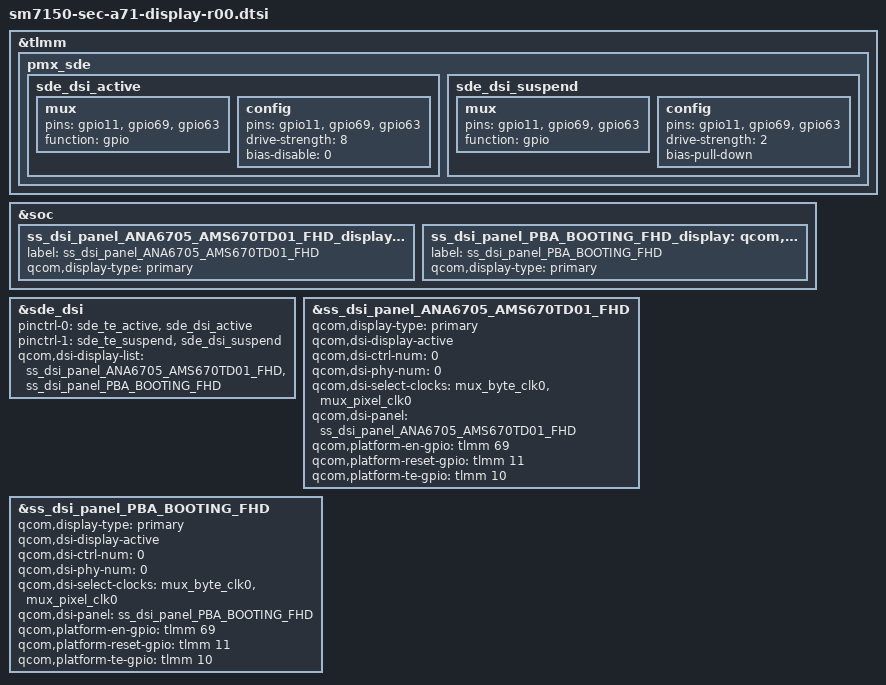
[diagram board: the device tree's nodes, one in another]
/* Copyright (c) 2016-2019, The Linux Foundation. All rights reserved.
 *
 * This program is free software; you can redistribute it and/or modify
 * it under the terms of the GNU General Public License version 2 and
 * only version 2 as published by the Free Software Foundation.
 *
 * This program is distributed in the hope that it will be useful,
 * but WITHOUT ANY WARRANTY; without even the implied warranty of
 * MERCHANTABILITY or FITNESS FOR A PARTICULAR PURPOSE.  See the
 * GNU General Public License for more details.
 */

#include "../../../../../../drivers/gpu/drm/msm/samsung/ANA6705_AMS670TD01/dsi_panel_ANA6705_AMS670TD01_fhd_octa_cmd.dtsi"
#include "../../../../../../drivers/gpu/drm/msm/samsung/PBA_BOOTING/dsi_panel_PBA_BOOTING_fhd_video.dtsi"


&tlmm {
	pmx_sde: pmx_sde {
		sde_dsi_active: sde_dsi_active {
			mux {
				pins = "gpio11","gpio69", "gpio63";
				function = "gpio";
			};

			config {
				pins = "gpio11","gpio69", "gpio63";
				drive-strength = <8>;   /* 8 mA */
				bias-disable = <0>;   /* no pull */
			};
		};
		sde_dsi_suspend: sde_dsi_suspend {
			mux {
				pins = "gpio11","gpio69", "gpio63";
				function = "gpio";
			};

			config {
				pins = "gpio11","gpio69", "gpio63";
				drive-strength = <2>;   /* 2 mA */
				bias-pull-down;         /* PULL DOWN */
			};
		};
	};
};

&soc {
	/* A70s panel */
	ss_dsi_panel_ANA6705_AMS670TD01_FHD_display: qcom,dsi-display@9 {
		label = "ss_dsi_panel_ANA6705_AMS670TD01_FHD";
		qcom,display-type = "primary";

	};

	/* PBA */
	ss_dsi_panel_PBA_BOOTING_FHD_display: qcom,dsi-display@10 {
		label = "ss_dsi_panel_PBA_BOOTING_FHD";
		qcom,display-type = "primary";

	};
};

&sde_dsi {
	pinctrl-names = "panel_active", "panel_suspend";
	pinctrl-0 = <&sde_te_active  &sde_dsi_active>;
	pinctrl-1 = <&sde_te_suspend  &sde_dsi_suspend>;
	qcom,dsi-display-list =
		<&ss_dsi_panel_ANA6705_AMS670TD01_FHD
		&ss_dsi_panel_PBA_BOOTING_FHD>;
};

&ss_dsi_panel_ANA6705_AMS670TD01_FHD {
	qcom,display-type = "primary";
	qcom,dsi-display-active;

	qcom,dsi-ctrl-num = <0>;
	qcom,dsi-phy-num = <0>;
	qcom,dsi-select-clocks = "mux_byte_clk0", "mux_pixel_clk0";

	qcom,dsi-panel = <&ss_dsi_panel_ANA6705_AMS670TD01_FHD>;

	qcom,platform-en-gpio = <&tlmm 69 0>; 		/* LCD_EN_3P0 */
	qcom,platform-reset-gpio = <&tlmm 11 0>;    /* OCTA_RST_N */
	qcom,platform-te-gpio = <&tlmm 10 0>;		/* DISP_TE	  */
};

&ss_dsi_panel_PBA_BOOTING_FHD {
	qcom,display-type = "primary";
	qcom,dsi-display-active;

	qcom,dsi-ctrl-num = <0>;
	qcom,dsi-phy-num = <0>;
	qcom,dsi-select-clocks = "mux_byte_clk0", "mux_pixel_clk0";

	qcom,dsi-panel = <&ss_dsi_panel_PBA_BOOTING_FHD>;

	qcom,platform-en-gpio = <&tlmm 69 0>;
	qcom,platform-reset-gpio = <&tlmm 11 0>;
	qcom,platform-te-gpio = <&tlmm 10 0>;
};

